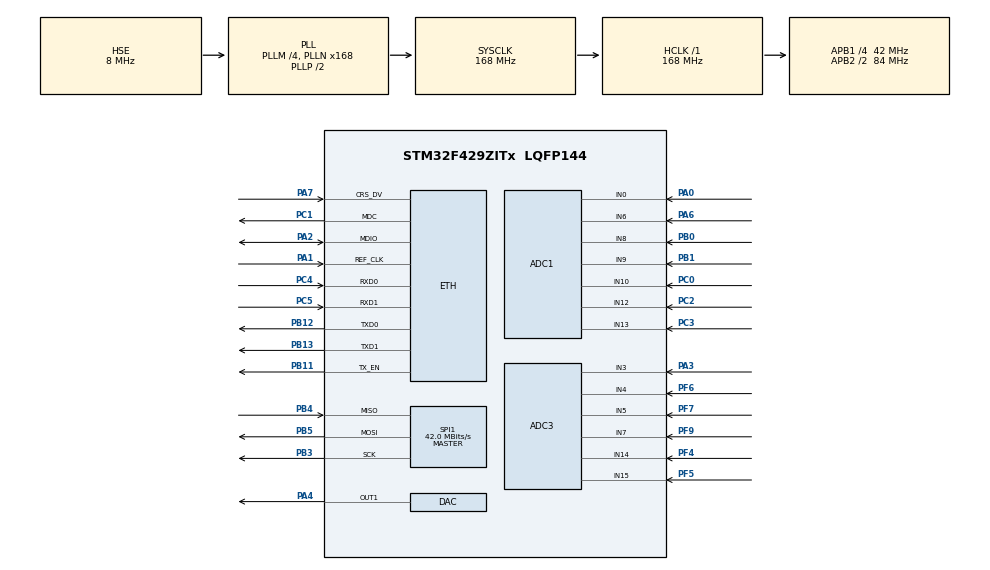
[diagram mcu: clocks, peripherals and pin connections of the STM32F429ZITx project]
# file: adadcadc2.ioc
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ADC1.Channel-0\#ChannelRegularConversion=ADC_CHANNEL_0
ADC1.Channel-1\#ChannelRegularConversion=ADC_CHANNEL_6
ADC1.Channel-2\#ChannelRegularConversion=ADC_CHANNEL_8
ADC1.Channel-3\#ChannelRegularConversion=ADC_CHANNEL_9
ADC1.Channel-4\#ChannelRegularConversion=ADC_CHANNEL_10
ADC1.Channel-5\#ChannelRegularConversion=ADC_CHANNEL_12
ADC1.Channel-6\#ChannelRegularConversion=ADC_CHANNEL_13
ADC1.ContinuousConvMode=ENABLE
ADC1.DMAContinuousRequests=ENABLE
ADC1.NbrOfConversion=7
ADC1.NbrOfConversionFlag=1
ADC1.Rank-0\#ChannelRegularConversion=1
ADC1.Rank-1\#ChannelRegularConversion=2
ADC1.Rank-2\#ChannelRegularConversion=3
ADC1.Rank-3\#ChannelRegularConversion=4
ADC1.Rank-4\#ChannelRegularConversion=5
ADC1.Rank-5\#ChannelRegularConversion=6
ADC1.Rank-6\#ChannelRegularConversion=7
ADC1.SamplingTime-0\#ChannelRegularConversion=ADC_SAMPLETIME_3CYCLES
ADC1.SamplingTime-1\#ChannelRegularConversion=ADC_SAMPLETIME_3CYCLES
ADC1.SamplingTime-2\#ChannelRegularConversion=ADC_SAMPLETIME_3CYCLES
ADC1.SamplingTime-3\#ChannelRegularConversion=ADC_SAMPLETIME_3CYCLES
ADC1.SamplingTime-4\#ChannelRegularConversion=ADC_SAMPLETIME_3CYCLES
ADC1.SamplingTime-5\#ChannelRegularConversion=ADC_SAMPLETIME_3CYCLES
ADC1.SamplingTime-6\#ChannelRegularConversion=ADC_SAMPLETIME_3CYCLES
ADC1.ScanConvMode=ENABLE
ADC1.master=1
ADC3.Channel-1\#ChannelRegularConversion=ADC_CHANNEL_3
ADC3.Channel-2\#ChannelRegularConversion=ADC_CHANNEL_4
ADC3.Channel-3\#ChannelRegularConversion=ADC_CHANNEL_5
ADC3.Channel-4\#ChannelRegularConversion=ADC_CHANNEL_7
ADC3.Channel-5\#ChannelRegularConversion=ADC_CHANNEL_14
ADC3.Channel-6\#ChannelRegularConversion=ADC_CHANNEL_15
ADC3.ContinuousConvMode=ENABLE
ADC3.DMAContinuousRequests=ENABLE
ADC3.NbrOfConversion=6
ADC3.NbrOfConversionFlag=1
ADC3.Rank-1\#ChannelRegularConversion=1
ADC3.Rank-2\#ChannelRegularConversion=2
ADC3.Rank-3\#ChannelRegularConversion=3
ADC3.Rank-4\#ChannelRegularConversion=4
ADC3.Rank-5\#ChannelRegularConversion=5
ADC3.Rank-6\#ChannelRegularConversion=6
ADC3.SamplingTime-1\#ChannelRegularConversion=ADC_SAMPLETIME_3CYCLES
ADC3.SamplingTime-2\#ChannelRegularConversion=ADC_SAMPLETIME_3CYCLES
ADC3.SamplingTime-3\#ChannelRegularConversion=ADC_SAMPLETIME_3CYCLES
ADC3.SamplingTime-4\#ChannelRegularConversion=ADC_SAMPLETIME_3CYCLES
ADC3.SamplingTime-5\#ChannelRegularConversion=ADC_SAMPLETIME_3CYCLES
ADC3.SamplingTime-6\#ChannelRegularConversion=ADC_SAMPLETIME_3CYCLES
ADC3.ScanConvMode=ENABLE
Dma.ADC1.0.Direction=DMA_PERIPH_TO_MEMORY
Dma.ADC1.0.FIFOMode=DMA_FIFOMODE_DISABLE
Dma.ADC1.0.Instance=DMA2_Stream0
Dma.ADC1.0.MemDataAlignment=DMA_MDATAALIGN_HALFWORD
Dma.ADC1.0.MemInc=DMA_MINC_ENABLE
Dma.ADC1.0.Mode=DMA_CIRCULAR
Dma.ADC1.0.PeriphDataAlignment=DMA_PDATAALIGN_HALFWORD
Dma.ADC1.0.PeriphInc=DMA_PINC_DISABLE
Dma.ADC1.0.Priority=DMA_PRIORITY_LOW
Dma.ADC3.1.Direction=DMA_PERIPH_TO_MEMORY
Dma.ADC3.1.FIFOMode=DMA_FIFOMODE_DISABLE
Dma.ADC3.1.Instance=DMA2_Stream1
Dma.ADC3.1.MemDataAlignment=DMA_MDATAALIGN_HALFWORD
Dma.ADC3.1.MemInc=DMA_MINC_ENABLE
Dma.ADC3.1.Mode=DMA_CIRCULAR
Dma.ADC3.1.PeriphDataAlignment=DMA_PDATAALIGN_HALFWORD
Dma.ADC3.1.PeriphInc=DMA_PINC_DISABLE
Dma.ADC3.1.Priority=DMA_PRIORITY_LOW
Dma.Request0=ADC1
Dma.Request1=ADC3
ETH.MediaInterface=ETH_MEDIA_INTERFACE_RMII
Mcu.Family=STM32F4
Mcu.Name=STM32F429ZITx
Mcu.Package=LQFP144
NVIC.DMA2_Stream0_IRQn=true\:0\:0\:false\:false\:true\:false\:true
NVIC.DMA2_Stream1_IRQn=true\:0\:0\:false\:false\:true\:false\:true
NVIC.PriorityGroup=NVIC_PRIORITYGROUP_4
PA0/WKUP.Signal=ADCx_IN0
PA1.Mode=RMII
PA1.Signal=ETH_REF_CLK
PA2.Mode=RMII
PA2.Signal=ETH_MDIO
PA3.Signal=ADCx_IN3
PA4.Signal=COMP_DAC1_group
PA6.Signal=ADCx_IN6
PA7.Mode=RMII
PA7.Signal=ETH_CRS_DV
PB0.Signal=ADCx_IN8
PB1.Signal=ADCx_IN9
PB11.Mode=RMII
PB11.Signal=ETH_TX_EN
PB12.Mode=RMII
PB12.Signal=ETH_TXD0
PB13.Mode=RMII
PB13.Signal=ETH_TXD1
PB3.Mode=Full_Duplex_Master
PB3.Signal=SPI1_SCK
PB4.Mode=Full_Duplex_Master
PB4.Signal=SPI1_MISO
PB5.Mode=Full_Duplex_Master
PB5.Signal=SPI1_MOSI
PC0.Signal=ADCx_IN10
PC1.Mode=RMII
PC1.Signal=ETH_MDC
PC2.Signal=ADCx_IN12
PC3.Signal=ADCx_IN13
PC4.Mode=RMII
PC4.Signal=ETH_RXD0
PC5.Mode=RMII
PC5.Signal=ETH_RXD1
PF4.Mode=IN14
PF4.Signal=ADC3_IN14
PF5.Mode=IN15
PF5.Signal=ADC3_IN15
PF6.Mode=IN4
PF6.Signal=ADC3_IN4
PF7.Mode=IN5
PF7.Signal=ADC3_IN5
PF9.Mode=IN7
PF9.Signal=ADC3_IN7
PH0/OSC_IN.Mode=HSE-External-Oscillator
PH0/OSC_IN.Signal=RCC_OSC_IN
PH1/OSC_OUT.Mode=HSE-External-Oscillator
PH1/OSC_OUT.Signal=RCC_OSC_OUT
ProjectManager.HeapSize=0x200
ProjectManager.StackSize=0x400
ProjectManager.TargetToolchain=STM32CubeIDE
RCC.48MHZClocksFreq_Value=84000000
RCC.AHBFreq_Value=168000000
RCC.APB1CLKDivider=RCC_HCLK_DIV4
RCC.APB1Freq_Value=42000000
RCC.APB1TimFreq_Value=84000000
RCC.APB2CLKDivider=RCC_HCLK_DIV2
RCC.APB2Freq_Value=84000000
RCC.APB2TimFreq_Value=168000000
RCC.CortexFreq_Value=168000000
RCC.HCLKFreq_Value=168000000
RCC.HSE_VALUE=8000000
RCC.HSI_VALUE=16000000
RCC.LSE_VALUE=32768
RCC.PLLM=4
RCC.PLLN=168
RCC.PLLSourceVirtual=RCC_PLLSOURCE_HSE
RCC.SYSCLKFreq_VALUE=168000000
RCC.SYSCLKSource=RCC_SYSCLKSOURCE_PLLCLK
RCC.VCOOutputFreq_Value=336000000
SH.ADCx_IN0.0=ADC1_IN0,IN0
SH.ADCx_IN10.0=ADC1_IN10,IN10
SH.ADCx_IN12.0=ADC1_IN12,IN12
SH.ADCx_IN13.0=ADC1_IN13,IN13
SH.ADCx_IN3.0=ADC3_IN3,IN3
SH.ADCx_IN6.0=ADC1_IN6,IN6
SH.ADCx_IN8.0=ADC1_IN8,IN8
SH.ADCx_IN9.0=ADC1_IN9,IN9
SH.COMP_DAC1_group.0=DAC_OUT1,DAC_OUT1
SPI1.CalculateBaudRate=42.0 MBits/s
SPI1.Direction=SPI_DIRECTION_2LINES
SPI1.Mode=SPI_MODE_MASTER
SPI1.VirtualType=VM_MASTER
board=custom

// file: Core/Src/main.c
/* USER CODE BEGIN Header */
/**
  ******************************************************************************
  * @file           : main.c
  * @brief          : Main program body
  ******************************************************************************
  * @attention
  *
  * <h2><center>&copy; Copyright (c) 2019 STMicroelectronics.
  * All rights reserved.</center></h2>
  *
  * This software component is licensed by ST under BSD 3-Clause license,
  * the "License"; You may not use this file except in compliance with the
  * License. You may obtain a copy of the License at:
  *                        opensource.org/licenses/BSD-3-Clause
  *
  ******************************************************************************
  */
/* USER CODE END Header */

#include "main.h"
#include "adc.h"
#include "dac.h"
#include "dma.h"
#include "eth.h"
#include "spi.h"
#include "gpio.h"

void SystemClock_Config(void);

/* USER CODE BEGIN 0 */
uint16_t adc[7];
uint16_t adc3[6];
/* USER CODE END 0 */

int main(void)
{

  /* MCU Configuration--------------------------------------------------------*/

  /* Reset of all peripherals, Initializes the Flash interface and the Systick. */
  HAL_Init();

  /* Configure the system clock */
  SystemClock_Config();

  /* Initialize all configured peripherals */
  MX_GPIO_Init();
  MX_DMA_Init();
  MX_ADC1_Init();
  MX_DAC_Init();
  MX_ETH_Init();
  MX_SPI1_Init();
  MX_ADC3_Init();
  /* USER CODE BEGIN 2 */
  HAL_ADC_Start_DMA(&hadc1, adc, 7);
  HAL_ADC_Start_DMA(&hadc3, adc3, 6);
  /* USER CODE END 2 */

  /* Infinite loop */
  while (1)
  {

  }
}

void SystemClock_Config(void)
{
  RCC_OscInitTypeDef RCC_OscInitStruct = {0};
  RCC_ClkInitTypeDef RCC_ClkInitStruct = {0};

  /** Configure the main internal regulator output voltage
  */
  __HAL_RCC_PWR_CLK_ENABLE();
  __HAL_PWR_VOLTAGESCALING_CONFIG(PWR_REGULATOR_VOLTAGE_SCALE1);
  /** Initializes the CPU, AHB and APB busses clocks
  */
  RCC_OscInitStruct.OscillatorType = RCC_OSCILLATORTYPE_HSE;
  RCC_OscInitStruct.HSEState = RCC_HSE_ON;
  RCC_OscInitStruct.PLL.PLLState = RCC_PLL_ON;
  RCC_OscInitStruct.PLL.PLLSource = RCC_PLLSOURCE_HSE;
  RCC_OscInitStruct.PLL.PLLM = 4;
  RCC_OscInitStruct.PLL.PLLN = 168;
  RCC_OscInitStruct.PLL.PLLP = RCC_PLLP_DIV2;
  RCC_OscInitStruct.PLL.PLLQ = 4;
  if (HAL_RCC_OscConfig(&RCC_OscInitStruct) != HAL_OK)
  {
    Error_Handler();
  }
  /** Initializes the CPU, AHB and APB busses clocks
  */
  RCC_ClkInitStruct.ClockType = RCC_CLOCKTYPE_HCLK|RCC_CLOCKTYPE_SYSCLK
                              |RCC_CLOCKTYPE_PCLK1|RCC_CLOCKTYPE_PCLK2;
  RCC_ClkInitStruct.SYSCLKSource = RCC_SYSCLKSOURCE_PLLCLK;
  RCC_ClkInitStruct.AHBCLKDivider = RCC_SYSCLK_DIV1;
  RCC_ClkInitStruct.APB1CLKDivider = RCC_HCLK_DIV4;
  RCC_ClkInitStruct.APB2CLKDivider = RCC_HCLK_DIV2;

  if (HAL_RCC_ClockConfig(&RCC_ClkInitStruct, FLASH_LATENCY_5) != HAL_OK)
  {
    Error_Handler();
  }
}

void Error_Handler(void)
{
}

/************************ (C) COPYRIGHT STMicroelectronics *****END OF FILE****/
